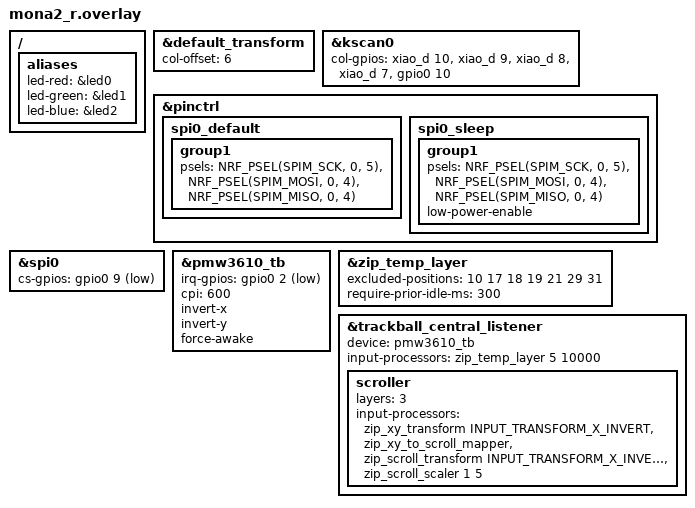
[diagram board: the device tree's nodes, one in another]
#include "mona2.dtsi"
#include <input/processors.dtsi>
#include <zephyr/dt-bindings/input/input-event-codes.h>

/ {
    aliases {
        led-red   = &led0;
        led-green = &led1;
        led-blue  = &led2;
    };
};


&default_transform {
    col-offset = <6>;
};

&kscan0 {
        col-gpios
            = <&xiao_d 10 GPIO_ACTIVE_HIGH>
            , <&xiao_d 9 GPIO_ACTIVE_HIGH> 
            , <&xiao_d 8 GPIO_ACTIVE_HIGH> 
            , <&xiao_d 7 GPIO_ACTIVE_HIGH> 
            , <&gpio0 10 GPIO_ACTIVE_HIGH>
            ;
};


&pinctrl {
    spi0_default: spi0_default {    //通常時(SPI通信中)のピン構成
        group1 {
            psels = <NRF_PSEL(SPIM_SCK, 0, 5)>, //P0.05を指定(SCLK)
                <NRF_PSEL(SPIM_MOSI, 0, 4)>,    //P0.04を指定(SDIOだからMOSI,MISO両方の役割を担う)
                <NRF_PSEL(SPIM_MISO, 0, 4)>;
        };
    };

    spi0_sleep: spi0_sleep {    //スリープ時のピン構成(省電力)
        group1 {
            psels = <NRF_PSEL(SPIM_SCK, 0, 5)>,
                <NRF_PSEL(SPIM_MOSI, 0, 4)>,
                <NRF_PSEL(SPIM_MISO, 0, 4)>;
            low-power-enable;
        };
    };
};


// SPIバス: 右側のCS GPIOピンでオーバーライド (P0.09)
&spi0 {
    cs-gpios = <&gpio0 9 GPIO_ACTIVE_LOW>;  //P0.09を指定(CS)
};

// mona2.dtsiで定義済みのpmw3610_tbを右側ピン設定でオーバーライド
&pmw3610_tb {
    irq-gpios = <&gpio0 2 (GPIO_ACTIVE_LOW | GPIO_PULL_UP)>; //P0.02を指定(MOTION)
    cpi = <600>;
    //swap-xy;
    invert-x; //COROPIT版ではコメントアウトを外す
    invert-y; //COROPIT版ではコメントアウトを外す
    force-awake; // ZMKがアクティブな間センサーを起きたままにする
};

&zip_temp_layer {
    excluded-positions = <10 17 18 19 21 29 31>;
    require-prior-idle-ms = <300>;  // 好きなmsに調整（例: 300ms）
};

// Overrides for the input listener node
&trackball_central_listener {
    status = "okay";
    device = <&pmw3610_tb>;

    input-processors = <&zip_temp_layer 5 10000>; 

    scroller {
        layers = <3>;
        input-processors = 
            // <&zip_xy_transform INPUT_TRANSFORM_XY_SWAP>,        //X軸とY軸の入れ替え
            <&zip_xy_transform INPUT_TRANSFORM_X_INVERT>,       //X軸反転
            <&zip_xy_to_scroll_mapper>,                         //スクロールモードに変更
            <&zip_scroll_transform INPUT_TRANSFORM_X_INVERT>,   //スクロールのX軸反転
            <&zip_scroll_scaler 1 5>;                           //スクロール量を1/4倍
    };

};
